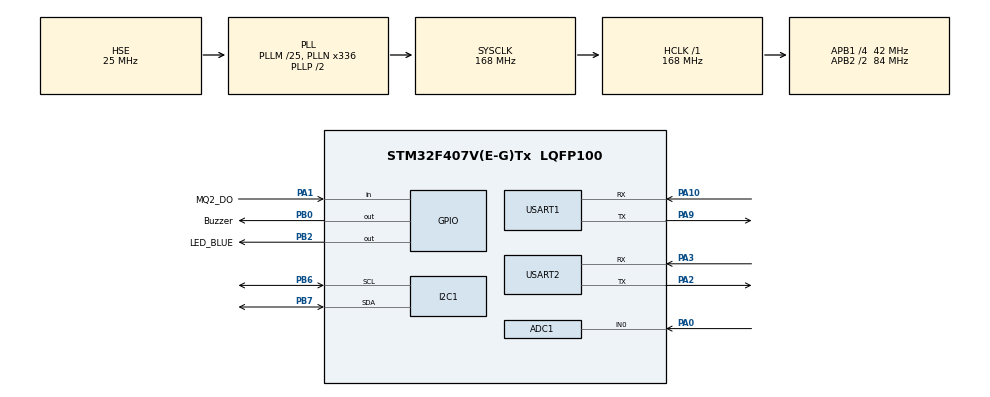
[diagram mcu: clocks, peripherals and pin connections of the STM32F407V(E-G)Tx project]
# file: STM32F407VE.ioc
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ADC1.Channel-2\#ChannelRegularConversion=ADC_CHANNEL_0
ADC1.NbrOfConversionFlag=1
ADC1.Rank-2\#ChannelRegularConversion=1
ADC1.SamplingTime-2\#ChannelRegularConversion=ADC_SAMPLETIME_15CYCLES
ADC1.master=1
I2C1.NoStretchMode=I2C_NOSTRETCH_DISABLE
I2C1.OwnAddress=0
Mcu.Family=STM32F4
Mcu.Name=STM32F407V(E-G)Tx
Mcu.Package=LQFP100
NVIC.PriorityGroup=NVIC_PRIORITYGROUP_4
PA0-WKUP.Signal=ADCx_IN0
PA1.GPIO_Label=MQ2_DO
PA1.GPIO_PuPd=GPIO_NOPULL
PA1.Signal=GPIO_Input
PA10.Mode=Asynchronous
PA10.Signal=USART1_RX
PA13.Mode=Serial_Wire
PA13.Signal=SYS_JTMS-SWDIO
PA14.Mode=Serial_Wire
PA14.Signal=SYS_JTCK-SWCLK
PA2.Mode=Asynchronous
PA2.Signal=USART2_TX
PA3.Mode=Asynchronous
PA3.Signal=USART2_RX
PA9.Mode=Asynchronous
PA9.Signal=USART1_TX
PB0.GPIO_Label=Buzzer
PB0.PinState=GPIO_PIN_SET
PB0.Signal=GPIO_Output
PB2.GPIO_Label=LED_BLUE
PB2.GPIO_PuPd=GPIO_NOPULL
PB2.PinState=GPIO_PIN_SET
PB2.Signal=GPIO_Output
PB6.Mode=I2C
PB6.Signal=I2C1_SCL
PB7.Mode=I2C
PB7.Signal=I2C1_SDA
PH0-OSC_IN.Mode=HSE-External-Oscillator
PH0-OSC_IN.Signal=RCC_OSC_IN
PH1-OSC_OUT.Mode=HSE-External-Oscillator
PH1-OSC_OUT.Signal=RCC_OSC_OUT
ProjectManager.HeapSize=0x1000
ProjectManager.StackSize=0x1000
ProjectManager.TargetToolchain=MDK-ARM V5.32
RCC.48MHZClocksFreq_Value=84000000
RCC.AHBFreq_Value=168000000
RCC.APB1CLKDivider=RCC_HCLK_DIV4
RCC.APB1Freq_Value=42000000
RCC.APB1TimFreq_Value=84000000
RCC.APB2CLKDivider=RCC_HCLK_DIV2
RCC.APB2Freq_Value=84000000
RCC.APB2TimFreq_Value=168000000
RCC.CortexFreq_Value=168000000
RCC.HCLKFreq_Value=168000000
RCC.HSE_VALUE=25000000
RCC.HSI_VALUE=16000000
RCC.LSE_VALUE=32768
RCC.PLLM=25
RCC.PLLN=336
RCC.PLLSourceVirtual=RCC_PLLSOURCE_HSE
RCC.SYSCLKFreq_VALUE=168000000
RCC.SYSCLKSource=RCC_SYSCLKSOURCE_PLLCLK
RCC.VCOOutputFreq_Value=336000000
SH.ADCx_IN0.0=ADC1_IN0,IN0
USART1.VirtualMode=VM_ASYNC
USART2.VirtualMode=VM_ASYNC
board=custom

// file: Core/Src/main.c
/* USER CODE BEGIN Header */
/**
  ******************************************************************************
  * @file           : main.c
  * @brief          : Main program body
  ******************************************************************************
  * @attention
  *
  * Copyright (c) 2026 STMicroelectronics.
  * All rights reserved.
  *
  * This software is licensed under terms that can be found in the LICENSE file
  * in the root directory of this software component.
  * If no LICENSE file comes with this software, it is provided AS-IS.
  *
  ******************************************************************************
  */
/* USER CODE END Header */
#include "main.h"
#include "adc.h"
#include "i2c.h"
#include "usart.h"
#include "gpio.h"

/* USER CODE BEGIN Includes */
#include <stdio.h>
#include "fun.h"

/* USER CODE END Includes */

void SystemClock_Config(void);

/* USER CODE BEGIN 0 */

#ifdef __GNUC__
#define PUTCHAR_PROTOTYPE int __io_putchar(int ch)
#else
#define PUTCHAR_PROTOTYPE int fputc(int ch, FILE *f)
#endif

PUTCHAR_PROTOTYPE
{
		HAL_UART_Transmit(&huart1, (uint8_t *)&ch, 1, HAL_MAX_DELAY);
		return ch;
}
/* USER CODE END 0 */

int main(void)
{

  /* MCU Configuration--------------------------------------------------------*/

  /* Reset of all peripherals, Initializes the Flash interface and the Systick. */
  HAL_Init();

  /* Configure the system clock */
  SystemClock_Config();

  /* Initialize all configured peripherals */
  MX_GPIO_Init();
  MX_USART1_UART_Init();
  MX_I2C1_Init();
  MX_ADC1_Init();
  MX_USART2_UART_Init();
  /* USER CODE BEGIN 2 */
	printf("System STARTED!\r\n");
	printf("All OK.\r\n");
	MQ2_Calibrate(0.40f, 55);
  /* USER CODE END 2 */

  /* Infinite loop */
  /* USER CODE BEGIN WHILE */
  while (1)
  {
		Gas_Detection_System();
		//Gas_Detection_System();
    /* USER CODE END WHILE */

  }
}

void SystemClock_Config(void)
{
  RCC_OscInitTypeDef RCC_OscInitStruct = {0};
  RCC_ClkInitTypeDef RCC_ClkInitStruct = {0};

  /** Configure the main internal regulator output voltage
  */
  __HAL_RCC_PWR_CLK_ENABLE();
  __HAL_PWR_VOLTAGESCALING_CONFIG(PWR_REGULATOR_VOLTAGE_SCALE1);

  /** Initializes the RCC Oscillators according to the specified parameters
  * in the RCC_OscInitTypeDef structure.
  */
  RCC_OscInitStruct.OscillatorType = RCC_OSCILLATORTYPE_HSE;
  RCC_OscInitStruct.HSEState = RCC_HSE_ON;
  RCC_OscInitStruct.PLL.PLLState = RCC_PLL_ON;
  RCC_OscInitStruct.PLL.PLLSource = RCC_PLLSOURCE_HSE;
  RCC_OscInitStruct.PLL.PLLM = 25;
  RCC_OscInitStruct.PLL.PLLN = 336;
  RCC_OscInitStruct.PLL.PLLP = RCC_PLLP_DIV2;
  RCC_OscInitStruct.PLL.PLLQ = 4;
  if (HAL_RCC_OscConfig(&RCC_OscInitStruct) != HAL_OK)
  {
    Error_Handler();
  }

  /** Initializes the CPU, AHB and APB buses clocks
  */
  RCC_ClkInitStruct.ClockType = RCC_CLOCKTYPE_HCLK|RCC_CLOCKTYPE_SYSCLK
                              |RCC_CLOCKTYPE_PCLK1|RCC_CLOCKTYPE_PCLK2;
  RCC_ClkInitStruct.SYSCLKSource = RCC_SYSCLKSOURCE_PLLCLK;
  RCC_ClkInitStruct.AHBCLKDivider = RCC_SYSCLK_DIV1;
  RCC_ClkInitStruct.APB1CLKDivider = RCC_HCLK_DIV4;
  RCC_ClkInitStruct.APB2CLKDivider = RCC_HCLK_DIV2;

  if (HAL_RCC_ClockConfig(&RCC_ClkInitStruct, FLASH_LATENCY_5) != HAL_OK)
  {
    Error_Handler();
  }
}

void Error_Handler(void)
{
  __disable_irq();
  while (1)
  {
  }
}
